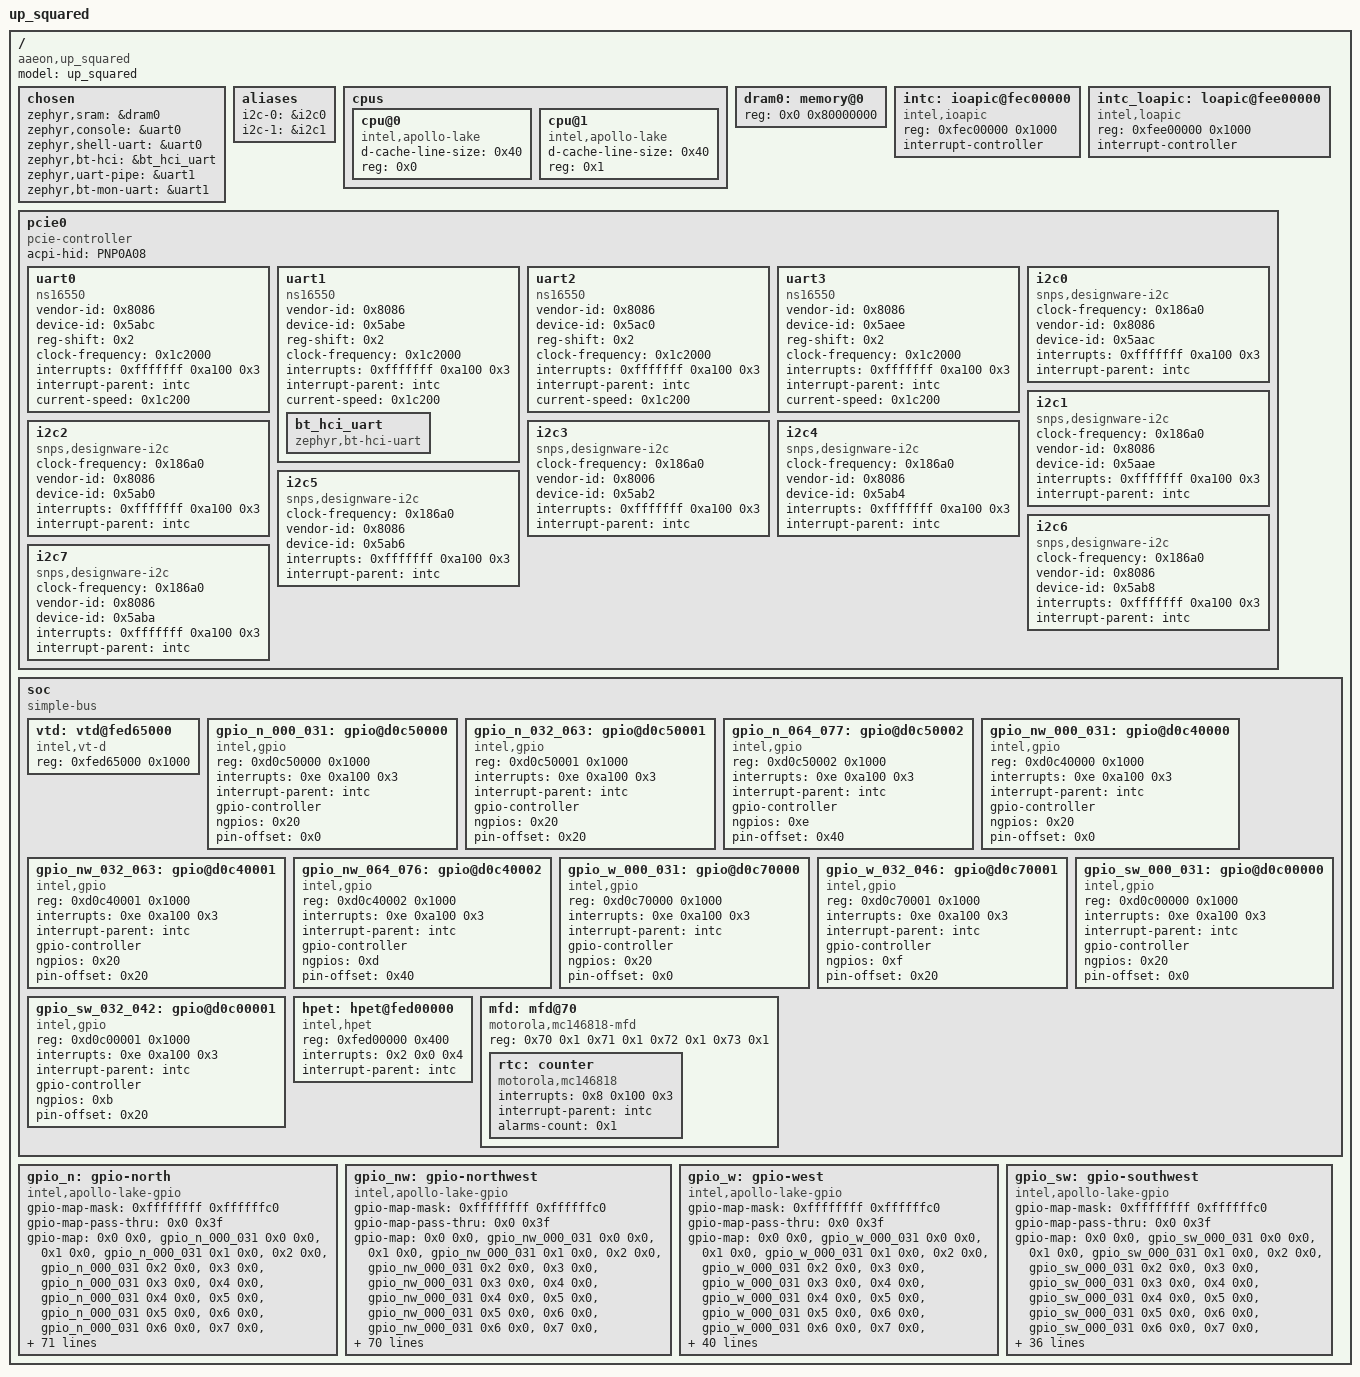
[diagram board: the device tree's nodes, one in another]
/dts-v1/;

/* node '/' defined in zephyr/dts/common/skeleton.dtsi:9 */
/ {
	#address-cells = < 0x1 >;        /* in zephyr/dts/common/skeleton.dtsi:10 */
	#size-cells = < 0x1 >;           /* in zephyr/dts/common/skeleton.dtsi:11 */
	model = "up_squared";            /* in zephyr/boards/up-bridge-the-gap/up_squared/up_squared.dts:16 */
	compatible = "aaeon,up_squared"; /* in zephyr/boards/up-bridge-the-gap/up_squared/up_squared.dts:17 */

	/* node '/chosen' defined in zephyr/dts/common/skeleton.dtsi:13 */
	chosen {
		zephyr,sram = &dram0;         /* in zephyr/boards/up-bridge-the-gap/up_squared/up_squared.dts:25 */
		zephyr,console = &uart0;      /* in zephyr/boards/up-bridge-the-gap/up_squared/up_squared.dts:26 */
		zephyr,shell-uart = &uart0;   /* in zephyr/boards/up-bridge-the-gap/up_squared/up_squared.dts:27 */
		zephyr,bt-hci = &bt_hci_uart; /* in zephyr/boards/up-bridge-the-gap/up_squared/up_squared.dts:28 */
		zephyr,uart-pipe = &uart1;    /* in zephyr/boards/up-bridge-the-gap/up_squared/up_squared.dts:29 */
		zephyr,bt-mon-uart = &uart1;  /* in zephyr/boards/up-bridge-the-gap/up_squared/up_squared.dts:30 */
	};

	/* node '/aliases' defined in zephyr/dts/common/skeleton.dtsi:15 */
	aliases {
		i2c-0 = &i2c0; /* in zephyr/boards/up-bridge-the-gap/up_squared/up_squared.dts:20 */
		i2c-1 = &i2c1; /* in zephyr/boards/up-bridge-the-gap/up_squared/up_squared.dts:21 */
	};

	/* node '/cpus' defined in zephyr/dts/x86/intel/apollo_lake.dtsi:13 */
	cpus {
		#address-cells = < 0x1 >; /* in zephyr/boards/up-bridge-the-gap/up_squared/up_squared.dts:34 */
		#size-cells = < 0x0 >;    /* in zephyr/boards/up-bridge-the-gap/up_squared/up_squared.dts:35 */

		/* node '/cpus/cpu@0' defined in zephyr/dts/x86/intel/apollo_lake.dtsi:17 */
		cpu@0 {
			device_type = "cpu";              /* in zephyr/boards/up-bridge-the-gap/up_squared/up_squared.dts:38 */
			compatible = "intel,apollo-lake",
			             "intel,x86_64";      /* in zephyr/boards/up-bridge-the-gap/up_squared/up_squared.dts:39 */
			d-cache-line-size = < 0x40 >;     /* in zephyr/boards/up-bridge-the-gap/up_squared/up_squared.dts:40 */
			reg = < 0x0 >;                    /* in zephyr/boards/up-bridge-the-gap/up_squared/up_squared.dts:41 */
		};

		/* node '/cpus/cpu@1' defined in zephyr/boards/up-bridge-the-gap/up_squared/up_squared.dts:44 */
		cpu@1 {
			device_type = "cpu";              /* in zephyr/boards/up-bridge-the-gap/up_squared/up_squared.dts:45 */
			compatible = "intel,apollo-lake",
			             "intel,x86_64";      /* in zephyr/boards/up-bridge-the-gap/up_squared/up_squared.dts:46 */
			d-cache-line-size = < 0x40 >;     /* in zephyr/boards/up-bridge-the-gap/up_squared/up_squared.dts:47 */
			reg = < 0x1 >;                    /* in zephyr/boards/up-bridge-the-gap/up_squared/up_squared.dts:48 */
		};
	};

	/* node '/memory@0' defined in zephyr/dts/x86/intel/apollo_lake.dtsi:25 */
	dram0: memory@0 {
		device_type = "memory";   /* in zephyr/dts/x86/intel/apollo_lake.dtsi:26 */
		reg = < 0x0 0x80000000 >; /* in zephyr/dts/x86/intel/apollo_lake.dtsi:27 */
	};

	/* node '/ioapic@fec00000' defined in zephyr/dts/x86/intel/apollo_lake.dtsi:30 */
	intc: ioapic@fec00000 {
		compatible = "intel,ioapic"; /* in zephyr/dts/x86/intel/apollo_lake.dtsi:31 */
		#address-cells = < 0x1 >;    /* in zephyr/dts/x86/intel/apollo_lake.dtsi:32 */
		#interrupt-cells = < 0x3 >;  /* in zephyr/dts/x86/intel/apollo_lake.dtsi:33 */
		reg = < 0xfec00000 0x1000 >; /* in zephyr/dts/x86/intel/apollo_lake.dtsi:34 */
		interrupt-controller;        /* in zephyr/dts/x86/intel/apollo_lake.dtsi:35 */
		phandle = < 0x1 >;           /* in zephyr/dts/x86/intel/apollo_lake.dtsi:62 */
	};

	/* node '/loapic@fee00000' defined in zephyr/dts/x86/intel/apollo_lake.dtsi:38 */
	intc_loapic: loapic@fee00000 {
		compatible = "intel,loapic"; /* in zephyr/dts/x86/intel/apollo_lake.dtsi:39 */
		reg = < 0xfee00000 0x1000 >; /* in zephyr/dts/x86/intel/apollo_lake.dtsi:40 */
		interrupt-controller;        /* in zephyr/dts/x86/intel/apollo_lake.dtsi:41 */
		#interrupt-cells = < 0x3 >;  /* in zephyr/dts/x86/intel/apollo_lake.dtsi:42 */
		#address-cells = < 0x1 >;    /* in zephyr/dts/x86/intel/apollo_lake.dtsi:43 */
	};

	/* node '/pcie0' defined in zephyr/dts/x86/intel/apollo_lake.dtsi:46 */
	pcie0: pcie0 {
		#address-cells = < 0x1 >;       /* in zephyr/dts/x86/intel/apollo_lake.dtsi:47 */
		#size-cells = < 0x1 >;          /* in zephyr/dts/x86/intel/apollo_lake.dtsi:48 */
		compatible = "pcie-controller"; /* in zephyr/dts/x86/intel/apollo_lake.dtsi:49 */
		acpi-hid = "PNP0A08";           /* in zephyr/dts/x86/intel/apollo_lake.dtsi:50 */
		ranges;                         /* in zephyr/dts/x86/intel/apollo_lake.dtsi:51 */

		/* node '/pcie0/uart0' defined in zephyr/dts/x86/intel/apollo_lake.dtsi:53 */
		uart0: uart0 {
			compatible = "ns16550";                /* in zephyr/dts/x86/intel/apollo_lake.dtsi:54 */
			vendor-id = < 0x8086 >;                /* in zephyr/dts/x86/intel/apollo_lake.dtsi:56 */
			device-id = < 0x5abc >;                /* in zephyr/dts/x86/intel/apollo_lake.dtsi:57 */
			reg-shift = < 0x2 >;                   /* in zephyr/dts/x86/intel/apollo_lake.dtsi:59 */
			clock-frequency = < 0x1c2000 >;        /* in zephyr/dts/x86/intel/apollo_lake.dtsi:60 */
			interrupts = < 0xfffffff 0xa100 0x3 >; /* in zephyr/dts/x86/intel/apollo_lake.dtsi:61 */
			interrupt-parent = < &intc >;          /* in zephyr/dts/x86/intel/apollo_lake.dtsi:62 */
			status = "okay";                       /* in zephyr/dts/x86/intel/apollo_lake.dtsi:63 */
			current-speed = < 0x1c200 >;           /* in zephyr/dts/x86/intel/apollo_lake.dtsi:64 */
		};

		/* node '/pcie0/uart1' defined in zephyr/dts/x86/intel/apollo_lake.dtsi:67 */
		uart1: uart1 {
			compatible = "ns16550";                /* in zephyr/dts/x86/intel/apollo_lake.dtsi:68 */
			vendor-id = < 0x8086 >;                /* in zephyr/dts/x86/intel/apollo_lake.dtsi:70 */
			device-id = < 0x5abe >;                /* in zephyr/dts/x86/intel/apollo_lake.dtsi:71 */
			reg-shift = < 0x2 >;                   /* in zephyr/dts/x86/intel/apollo_lake.dtsi:73 */
			clock-frequency = < 0x1c2000 >;        /* in zephyr/dts/x86/intel/apollo_lake.dtsi:74 */
			interrupts = < 0xfffffff 0xa100 0x3 >; /* in zephyr/dts/x86/intel/apollo_lake.dtsi:75 */
			interrupt-parent = < &intc >;          /* in zephyr/dts/x86/intel/apollo_lake.dtsi:76 */
			status = "okay";                       /* in zephyr/dts/x86/intel/apollo_lake.dtsi:78 */
			current-speed = < 0x1c200 >;           /* in zephyr/dts/x86/intel/apollo_lake.dtsi:79 */

			/* node '/pcie0/uart1/bt_hci_uart' defined in zephyr/boards/up-bridge-the-gap/up_squared/up_squared.dts:54 */
			bt_hci_uart: bt_hci_uart {
				compatible = "zephyr,bt-hci-uart"; /* in zephyr/boards/up-bridge-the-gap/up_squared/up_squared.dts:55 */
				status = "okay";                   /* in zephyr/boards/up-bridge-the-gap/up_squared/up_squared.dts:56 */
			};
		};

		/* node '/pcie0/uart2' defined in zephyr/dts/x86/intel/apollo_lake.dtsi:82 */
		uart2: uart2 {
			compatible = "ns16550";                /* in zephyr/dts/x86/intel/apollo_lake.dtsi:83 */
			vendor-id = < 0x8086 >;                /* in zephyr/dts/x86/intel/apollo_lake.dtsi:85 */
			device-id = < 0x5ac0 >;                /* in zephyr/dts/x86/intel/apollo_lake.dtsi:86 */
			reg-shift = < 0x2 >;                   /* in zephyr/dts/x86/intel/apollo_lake.dtsi:88 */
			clock-frequency = < 0x1c2000 >;        /* in zephyr/dts/x86/intel/apollo_lake.dtsi:89 */
			interrupts = < 0xfffffff 0xa100 0x3 >; /* in zephyr/dts/x86/intel/apollo_lake.dtsi:90 */
			interrupt-parent = < &intc >;          /* in zephyr/dts/x86/intel/apollo_lake.dtsi:91 */
			status = "okay";                       /* in zephyr/dts/x86/intel/apollo_lake.dtsi:93 */
			current-speed = < 0x1c200 >;           /* in zephyr/dts/x86/intel/apollo_lake.dtsi:94 */
		};

		/* node '/pcie0/uart3' defined in zephyr/dts/x86/intel/apollo_lake.dtsi:97 */
		uart3: uart3 {
			compatible = "ns16550";                /* in zephyr/dts/x86/intel/apollo_lake.dtsi:98 */
			vendor-id = < 0x8086 >;                /* in zephyr/dts/x86/intel/apollo_lake.dtsi:100 */
			device-id = < 0x5aee >;                /* in zephyr/dts/x86/intel/apollo_lake.dtsi:101 */
			reg-shift = < 0x2 >;                   /* in zephyr/dts/x86/intel/apollo_lake.dtsi:103 */
			clock-frequency = < 0x1c2000 >;        /* in zephyr/dts/x86/intel/apollo_lake.dtsi:104 */
			interrupts = < 0xfffffff 0xa100 0x3 >; /* in zephyr/dts/x86/intel/apollo_lake.dtsi:105 */
			interrupt-parent = < &intc >;          /* in zephyr/dts/x86/intel/apollo_lake.dtsi:106 */
			status = "okay";                       /* in zephyr/dts/x86/intel/apollo_lake.dtsi:108 */
			current-speed = < 0x1c200 >;           /* in zephyr/dts/x86/intel/apollo_lake.dtsi:109 */
		};

		/* node '/pcie0/i2c0' defined in zephyr/dts/x86/intel/apollo_lake.dtsi:112 */
		i2c0: i2c0 {
			compatible = "snps,designware-i2c";    /* in zephyr/dts/x86/intel/apollo_lake.dtsi:113 */
			clock-frequency = < 0x186a0 >;         /* in zephyr/dts/x86/intel/apollo_lake.dtsi:114 */
			#address-cells = < 0x1 >;              /* in zephyr/dts/x86/intel/apollo_lake.dtsi:115 */
			#size-cells = < 0x0 >;                 /* in zephyr/dts/x86/intel/apollo_lake.dtsi:116 */
			vendor-id = < 0x8086 >;                /* in zephyr/dts/x86/intel/apollo_lake.dtsi:117 */
			device-id = < 0x5aac >;                /* in zephyr/dts/x86/intel/apollo_lake.dtsi:118 */
			interrupts = < 0xfffffff 0xa100 0x3 >; /* in zephyr/dts/x86/intel/apollo_lake.dtsi:119 */
			interrupt-parent = < &intc >;          /* in zephyr/dts/x86/intel/apollo_lake.dtsi:120 */
			status = "okay";                       /* in zephyr/dts/x86/intel/apollo_lake.dtsi:122 */
		};

		/* node '/pcie0/i2c1' defined in zephyr/dts/x86/intel/apollo_lake.dtsi:125 */
		i2c1: i2c1 {
			compatible = "snps,designware-i2c";    /* in zephyr/dts/x86/intel/apollo_lake.dtsi:126 */
			clock-frequency = < 0x186a0 >;         /* in zephyr/dts/x86/intel/apollo_lake.dtsi:127 */
			#address-cells = < 0x1 >;              /* in zephyr/dts/x86/intel/apollo_lake.dtsi:128 */
			#size-cells = < 0x0 >;                 /* in zephyr/dts/x86/intel/apollo_lake.dtsi:129 */
			vendor-id = < 0x8086 >;                /* in zephyr/dts/x86/intel/apollo_lake.dtsi:130 */
			device-id = < 0x5aae >;                /* in zephyr/dts/x86/intel/apollo_lake.dtsi:131 */
			interrupts = < 0xfffffff 0xa100 0x3 >; /* in zephyr/dts/x86/intel/apollo_lake.dtsi:132 */
			interrupt-parent = < &intc >;          /* in zephyr/dts/x86/intel/apollo_lake.dtsi:133 */
			status = "okay";                       /* in zephyr/dts/x86/intel/apollo_lake.dtsi:135 */
		};

		/* node '/pcie0/i2c2' defined in zephyr/dts/x86/intel/apollo_lake.dtsi:138 */
		i2c2: i2c2 {
			compatible = "snps,designware-i2c";    /* in zephyr/dts/x86/intel/apollo_lake.dtsi:139 */
			clock-frequency = < 0x186a0 >;         /* in zephyr/dts/x86/intel/apollo_lake.dtsi:140 */
			#address-cells = < 0x1 >;              /* in zephyr/dts/x86/intel/apollo_lake.dtsi:141 */
			#size-cells = < 0x0 >;                 /* in zephyr/dts/x86/intel/apollo_lake.dtsi:142 */
			vendor-id = < 0x8086 >;                /* in zephyr/dts/x86/intel/apollo_lake.dtsi:143 */
			device-id = < 0x5ab0 >;                /* in zephyr/dts/x86/intel/apollo_lake.dtsi:144 */
			interrupts = < 0xfffffff 0xa100 0x3 >; /* in zephyr/dts/x86/intel/apollo_lake.dtsi:145 */
			interrupt-parent = < &intc >;          /* in zephyr/dts/x86/intel/apollo_lake.dtsi:146 */
			status = "okay";                       /* in zephyr/dts/x86/intel/apollo_lake.dtsi:148 */
		};

		/* node '/pcie0/i2c3' defined in zephyr/dts/x86/intel/apollo_lake.dtsi:151 */
		i2c3: i2c3 {
			compatible = "snps,designware-i2c";    /* in zephyr/dts/x86/intel/apollo_lake.dtsi:152 */
			clock-frequency = < 0x186a0 >;         /* in zephyr/dts/x86/intel/apollo_lake.dtsi:153 */
			#address-cells = < 0x1 >;              /* in zephyr/dts/x86/intel/apollo_lake.dtsi:154 */
			#size-cells = < 0x0 >;                 /* in zephyr/dts/x86/intel/apollo_lake.dtsi:155 */
			vendor-id = < 0x8006 >;                /* in zephyr/dts/x86/intel/apollo_lake.dtsi:156 */
			device-id = < 0x5ab2 >;                /* in zephyr/dts/x86/intel/apollo_lake.dtsi:157 */
			interrupts = < 0xfffffff 0xa100 0x3 >; /* in zephyr/dts/x86/intel/apollo_lake.dtsi:158 */
			interrupt-parent = < &intc >;          /* in zephyr/dts/x86/intel/apollo_lake.dtsi:159 */
			status = "okay";                       /* in zephyr/dts/x86/intel/apollo_lake.dtsi:161 */
		};

		/* node '/pcie0/i2c4' defined in zephyr/dts/x86/intel/apollo_lake.dtsi:164 */
		i2c4: i2c4 {
			compatible = "snps,designware-i2c";    /* in zephyr/dts/x86/intel/apollo_lake.dtsi:165 */
			clock-frequency = < 0x186a0 >;         /* in zephyr/dts/x86/intel/apollo_lake.dtsi:166 */
			#address-cells = < 0x1 >;              /* in zephyr/dts/x86/intel/apollo_lake.dtsi:167 */
			#size-cells = < 0x0 >;                 /* in zephyr/dts/x86/intel/apollo_lake.dtsi:168 */
			vendor-id = < 0x8086 >;                /* in zephyr/dts/x86/intel/apollo_lake.dtsi:169 */
			device-id = < 0x5ab4 >;                /* in zephyr/dts/x86/intel/apollo_lake.dtsi:170 */
			interrupts = < 0xfffffff 0xa100 0x3 >; /* in zephyr/dts/x86/intel/apollo_lake.dtsi:171 */
			interrupt-parent = < &intc >;          /* in zephyr/dts/x86/intel/apollo_lake.dtsi:172 */
			status = "okay";                       /* in zephyr/dts/x86/intel/apollo_lake.dtsi:174 */
		};

		/* node '/pcie0/i2c5' defined in zephyr/dts/x86/intel/apollo_lake.dtsi:177 */
		i2c5: i2c5 {
			compatible = "snps,designware-i2c";    /* in zephyr/dts/x86/intel/apollo_lake.dtsi:178 */
			clock-frequency = < 0x186a0 >;         /* in zephyr/dts/x86/intel/apollo_lake.dtsi:179 */
			#address-cells = < 0x1 >;              /* in zephyr/dts/x86/intel/apollo_lake.dtsi:180 */
			#size-cells = < 0x0 >;                 /* in zephyr/dts/x86/intel/apollo_lake.dtsi:181 */
			vendor-id = < 0x8086 >;                /* in zephyr/dts/x86/intel/apollo_lake.dtsi:182 */
			device-id = < 0x5ab6 >;                /* in zephyr/dts/x86/intel/apollo_lake.dtsi:183 */
			interrupts = < 0xfffffff 0xa100 0x3 >; /* in zephyr/dts/x86/intel/apollo_lake.dtsi:184 */
			interrupt-parent = < &intc >;          /* in zephyr/dts/x86/intel/apollo_lake.dtsi:185 */
			status = "okay";                       /* in zephyr/dts/x86/intel/apollo_lake.dtsi:187 */
		};

		/* node '/pcie0/i2c6' defined in zephyr/dts/x86/intel/apollo_lake.dtsi:190 */
		i2c6: i2c6 {
			compatible = "snps,designware-i2c";    /* in zephyr/dts/x86/intel/apollo_lake.dtsi:191 */
			clock-frequency = < 0x186a0 >;         /* in zephyr/dts/x86/intel/apollo_lake.dtsi:192 */
			#address-cells = < 0x1 >;              /* in zephyr/dts/x86/intel/apollo_lake.dtsi:193 */
			#size-cells = < 0x0 >;                 /* in zephyr/dts/x86/intel/apollo_lake.dtsi:194 */
			vendor-id = < 0x8086 >;                /* in zephyr/dts/x86/intel/apollo_lake.dtsi:195 */
			device-id = < 0x5ab8 >;                /* in zephyr/dts/x86/intel/apollo_lake.dtsi:196 */
			interrupts = < 0xfffffff 0xa100 0x3 >; /* in zephyr/dts/x86/intel/apollo_lake.dtsi:197 */
			interrupt-parent = < &intc >;          /* in zephyr/dts/x86/intel/apollo_lake.dtsi:198 */
			status = "okay";                       /* in zephyr/dts/x86/intel/apollo_lake.dtsi:200 */
		};

		/* node '/pcie0/i2c7' defined in zephyr/dts/x86/intel/apollo_lake.dtsi:203 */
		i2c7: i2c7 {
			compatible = "snps,designware-i2c";    /* in zephyr/dts/x86/intel/apollo_lake.dtsi:204 */
			clock-frequency = < 0x186a0 >;         /* in zephyr/dts/x86/intel/apollo_lake.dtsi:205 */
			#address-cells = < 0x1 >;              /* in zephyr/dts/x86/intel/apollo_lake.dtsi:206 */
			#size-cells = < 0x0 >;                 /* in zephyr/dts/x86/intel/apollo_lake.dtsi:207 */
			vendor-id = < 0x8086 >;                /* in zephyr/dts/x86/intel/apollo_lake.dtsi:208 */
			device-id = < 0x5aba >;                /* in zephyr/dts/x86/intel/apollo_lake.dtsi:209 */
			interrupts = < 0xfffffff 0xa100 0x3 >; /* in zephyr/dts/x86/intel/apollo_lake.dtsi:210 */
			interrupt-parent = < &intc >;          /* in zephyr/dts/x86/intel/apollo_lake.dtsi:211 */
			status = "okay";                       /* in zephyr/dts/x86/intel/apollo_lake.dtsi:213 */
		};
	};

	/* node '/soc' defined in zephyr/dts/x86/intel/apollo_lake.dtsi:217 */
	soc {
		#address-cells = < 0x1 >;  /* in zephyr/dts/x86/intel/apollo_lake.dtsi:218 */
		#size-cells = < 0x1 >;     /* in zephyr/dts/x86/intel/apollo_lake.dtsi:219 */
		compatible = "simple-bus"; /* in zephyr/dts/x86/intel/apollo_lake.dtsi:220 */
		ranges;                    /* in zephyr/dts/x86/intel/apollo_lake.dtsi:221 */

		/* node '/soc/vtd@fed65000' defined in zephyr/dts/x86/intel/apollo_lake.dtsi:223 */
		vtd: vtd@fed65000 {
			compatible = "intel,vt-d";   /* in zephyr/dts/x86/intel/apollo_lake.dtsi:224 */
			reg = < 0xfed65000 0x1000 >; /* in zephyr/dts/x86/intel/apollo_lake.dtsi:226 */
			status = "okay";             /* in zephyr/dts/x86/intel/apollo_lake.dtsi:228 */
		};

		/* node '/soc/gpio@d0c50000' defined in zephyr/dts/x86/intel/apollo_lake.dtsi:231 */
		gpio_n_000_031: gpio@d0c50000 {
			compatible = "intel,gpio";       /* in zephyr/dts/x86/intel/apollo_lake.dtsi:232 */
			reg = < 0xd0c50000 0x1000 >;     /* in zephyr/dts/x86/intel/apollo_lake.dtsi:233 */
			interrupts = < 0xe 0xa100 0x3 >; /* in zephyr/dts/x86/intel/apollo_lake.dtsi:234 */
			interrupt-parent = < &intc >;    /* in zephyr/dts/x86/intel/apollo_lake.dtsi:235 */
			gpio-controller;                 /* in zephyr/dts/x86/intel/apollo_lake.dtsi:237 */
			#gpio-cells = < 0x2 >;           /* in zephyr/dts/x86/intel/apollo_lake.dtsi:238 */
			ngpios = < 0x20 >;               /* in zephyr/dts/x86/intel/apollo_lake.dtsi:240 */
			pin-offset = < 0x0 >;            /* in zephyr/dts/x86/intel/apollo_lake.dtsi:241 */
			status = "okay";                 /* in zephyr/dts/x86/intel/apollo_lake.dtsi:243 */
			phandle = < 0x2 >;               /* in zephyr/dts/x86/intel/apollo_lake.dtsi:414 */
		};

		/* node '/soc/gpio@d0c50001' defined in zephyr/dts/x86/intel/apollo_lake.dtsi:246 */
		gpio_n_032_063: gpio@d0c50001 {
			compatible = "intel,gpio";       /* in zephyr/dts/x86/intel/apollo_lake.dtsi:247 */
			reg = < 0xd0c50001 0x1000 >;     /* in zephyr/dts/x86/intel/apollo_lake.dtsi:248 */
			interrupts = < 0xe 0xa100 0x3 >; /* in zephyr/dts/x86/intel/apollo_lake.dtsi:249 */
			interrupt-parent = < &intc >;    /* in zephyr/dts/x86/intel/apollo_lake.dtsi:250 */
			gpio-controller;                 /* in zephyr/dts/x86/intel/apollo_lake.dtsi:252 */
			#gpio-cells = < 0x2 >;           /* in zephyr/dts/x86/intel/apollo_lake.dtsi:253 */
			ngpios = < 0x20 >;               /* in zephyr/dts/x86/intel/apollo_lake.dtsi:255 */
			pin-offset = < 0x20 >;           /* in zephyr/dts/x86/intel/apollo_lake.dtsi:256 */
			status = "okay";                 /* in zephyr/dts/x86/intel/apollo_lake.dtsi:258 */
			phandle = < 0x3 >;               /* in zephyr/dts/x86/intel/apollo_lake.dtsi:414 */
		};

		/* node '/soc/gpio@d0c50002' defined in zephyr/dts/x86/intel/apollo_lake.dtsi:261 */
		gpio_n_064_077: gpio@d0c50002 {
			compatible = "intel,gpio";       /* in zephyr/dts/x86/intel/apollo_lake.dtsi:262 */
			reg = < 0xd0c50002 0x1000 >;     /* in zephyr/dts/x86/intel/apollo_lake.dtsi:263 */
			interrupts = < 0xe 0xa100 0x3 >; /* in zephyr/dts/x86/intel/apollo_lake.dtsi:264 */
			interrupt-parent = < &intc >;    /* in zephyr/dts/x86/intel/apollo_lake.dtsi:265 */
			gpio-controller;                 /* in zephyr/dts/x86/intel/apollo_lake.dtsi:267 */
			#gpio-cells = < 0x2 >;           /* in zephyr/dts/x86/intel/apollo_lake.dtsi:268 */
			ngpios = < 0xe >;                /* in zephyr/dts/x86/intel/apollo_lake.dtsi:270 */
			pin-offset = < 0x40 >;           /* in zephyr/dts/x86/intel/apollo_lake.dtsi:271 */
			status = "okay";                 /* in zephyr/dts/x86/intel/apollo_lake.dtsi:273 */
			phandle = < 0x4 >;               /* in zephyr/dts/x86/intel/apollo_lake.dtsi:414 */
		};

		/* node '/soc/gpio@d0c40000' defined in zephyr/dts/x86/intel/apollo_lake.dtsi:276 */
		gpio_nw_000_031: gpio@d0c40000 {
			compatible = "intel,gpio";       /* in zephyr/dts/x86/intel/apollo_lake.dtsi:277 */
			reg = < 0xd0c40000 0x1000 >;     /* in zephyr/dts/x86/intel/apollo_lake.dtsi:278 */
			interrupts = < 0xe 0xa100 0x3 >; /* in zephyr/dts/x86/intel/apollo_lake.dtsi:279 */
			interrupt-parent = < &intc >;    /* in zephyr/dts/x86/intel/apollo_lake.dtsi:280 */
			gpio-controller;                 /* in zephyr/dts/x86/intel/apollo_lake.dtsi:282 */
			#gpio-cells = < 0x2 >;           /* in zephyr/dts/x86/intel/apollo_lake.dtsi:283 */
			ngpios = < 0x20 >;               /* in zephyr/dts/x86/intel/apollo_lake.dtsi:285 */
			pin-offset = < 0x0 >;            /* in zephyr/dts/x86/intel/apollo_lake.dtsi:286 */
			status = "okay";                 /* in zephyr/dts/x86/intel/apollo_lake.dtsi:288 */
			phandle = < 0x5 >;               /* in zephyr/dts/x86/intel/apollo_lake.dtsi:500 */
		};

		/* node '/soc/gpio@d0c40001' defined in zephyr/dts/x86/intel/apollo_lake.dtsi:291 */
		gpio_nw_032_063: gpio@d0c40001 {
			compatible = "intel,gpio";       /* in zephyr/dts/x86/intel/apollo_lake.dtsi:292 */
			reg = < 0xd0c40001 0x1000 >;     /* in zephyr/dts/x86/intel/apollo_lake.dtsi:293 */
			interrupts = < 0xe 0xa100 0x3 >; /* in zephyr/dts/x86/intel/apollo_lake.dtsi:294 */
			interrupt-parent = < &intc >;    /* in zephyr/dts/x86/intel/apollo_lake.dtsi:295 */
			gpio-controller;                 /* in zephyr/dts/x86/intel/apollo_lake.dtsi:297 */
			#gpio-cells = < 0x2 >;           /* in zephyr/dts/x86/intel/apollo_lake.dtsi:298 */
			ngpios = < 0x20 >;               /* in zephyr/dts/x86/intel/apollo_lake.dtsi:300 */
			pin-offset = < 0x20 >;           /* in zephyr/dts/x86/intel/apollo_lake.dtsi:301 */
			status = "okay";                 /* in zephyr/dts/x86/intel/apollo_lake.dtsi:303 */
			phandle = < 0x6 >;               /* in zephyr/dts/x86/intel/apollo_lake.dtsi:500 */
		};

		/* node '/soc/gpio@d0c40002' defined in zephyr/dts/x86/intel/apollo_lake.dtsi:306 */
		gpio_nw_064_076: gpio@d0c40002 {
			compatible = "intel,gpio";       /* in zephyr/dts/x86/intel/apollo_lake.dtsi:307 */
			reg = < 0xd0c40002 0x1000 >;     /* in zephyr/dts/x86/intel/apollo_lake.dtsi:308 */
			interrupts = < 0xe 0xa100 0x3 >; /* in zephyr/dts/x86/intel/apollo_lake.dtsi:309 */
			interrupt-parent = < &intc >;    /* in zephyr/dts/x86/intel/apollo_lake.dtsi:310 */
			gpio-controller;                 /* in zephyr/dts/x86/intel/apollo_lake.dtsi:312 */
			#gpio-cells = < 0x2 >;           /* in zephyr/dts/x86/intel/apollo_lake.dtsi:313 */
			ngpios = < 0xd >;                /* in zephyr/dts/x86/intel/apollo_lake.dtsi:315 */
			pin-offset = < 0x40 >;           /* in zephyr/dts/x86/intel/apollo_lake.dtsi:316 */
			status = "okay";                 /* in zephyr/dts/x86/intel/apollo_lake.dtsi:318 */
			phandle = < 0x7 >;               /* in zephyr/dts/x86/intel/apollo_lake.dtsi:500 */
		};

		/* node '/soc/gpio@d0c70000' defined in zephyr/dts/x86/intel/apollo_lake.dtsi:321 */
		gpio_w_000_031: gpio@d0c70000 {
			compatible = "intel,gpio";       /* in zephyr/dts/x86/intel/apollo_lake.dtsi:322 */
			reg = < 0xd0c70000 0x1000 >;     /* in zephyr/dts/x86/intel/apollo_lake.dtsi:323 */
			interrupts = < 0xe 0xa100 0x3 >; /* in zephyr/dts/x86/intel/apollo_lake.dtsi:324 */
			interrupt-parent = < &intc >;    /* in zephyr/dts/x86/intel/apollo_lake.dtsi:325 */
			gpio-controller;                 /* in zephyr/dts/x86/intel/apollo_lake.dtsi:327 */
			#gpio-cells = < 0x2 >;           /* in zephyr/dts/x86/intel/apollo_lake.dtsi:328 */
			ngpios = < 0x20 >;               /* in zephyr/dts/x86/intel/apollo_lake.dtsi:330 */
			pin-offset = < 0x0 >;            /* in zephyr/dts/x86/intel/apollo_lake.dtsi:331 */
			status = "okay";                 /* in zephyr/dts/x86/intel/apollo_lake.dtsi:333 */
			phandle = < 0x8 >;               /* in zephyr/dts/x86/intel/apollo_lake.dtsi:585 */
		};

		/* node '/soc/gpio@d0c70001' defined in zephyr/dts/x86/intel/apollo_lake.dtsi:336 */
		gpio_w_032_046: gpio@d0c70001 {
			compatible = "intel,gpio";       /* in zephyr/dts/x86/intel/apollo_lake.dtsi:337 */
			reg = < 0xd0c70001 0x1000 >;     /* in zephyr/dts/x86/intel/apollo_lake.dtsi:338 */
			interrupts = < 0xe 0xa100 0x3 >; /* in zephyr/dts/x86/intel/apollo_lake.dtsi:339 */
			interrupt-parent = < &intc >;    /* in zephyr/dts/x86/intel/apollo_lake.dtsi:340 */
			gpio-controller;                 /* in zephyr/dts/x86/intel/apollo_lake.dtsi:342 */
			#gpio-cells = < 0x2 >;           /* in zephyr/dts/x86/intel/apollo_lake.dtsi:343 */
			ngpios = < 0xf >;                /* in zephyr/dts/x86/intel/apollo_lake.dtsi:345 */
			pin-offset = < 0x20 >;           /* in zephyr/dts/x86/intel/apollo_lake.dtsi:346 */
			status = "okay";                 /* in zephyr/dts/x86/intel/apollo_lake.dtsi:348 */
			phandle = < 0x9 >;               /* in zephyr/dts/x86/intel/apollo_lake.dtsi:585 */
		};

		/* node '/soc/gpio@d0c00000' defined in zephyr/dts/x86/intel/apollo_lake.dtsi:351 */
		gpio_sw_000_031: gpio@d0c00000 {
			compatible = "intel,gpio";       /* in zephyr/dts/x86/intel/apollo_lake.dtsi:352 */
			reg = < 0xd0c00000 0x1000 >;     /* in zephyr/dts/x86/intel/apollo_lake.dtsi:353 */
			interrupts = < 0xe 0xa100 0x3 >; /* in zephyr/dts/x86/intel/apollo_lake.dtsi:354 */
			interrupt-parent = < &intc >;    /* in zephyr/dts/x86/intel/apollo_lake.dtsi:355 */
			gpio-controller;                 /* in zephyr/dts/x86/intel/apollo_lake.dtsi:357 */
			#gpio-cells = < 0x2 >;           /* in zephyr/dts/x86/intel/apollo_lake.dtsi:358 */
			ngpios = < 0x20 >;               /* in zephyr/dts/x86/intel/apollo_lake.dtsi:360 */
			pin-offset = < 0x0 >;            /* in zephyr/dts/x86/intel/apollo_lake.dtsi:361 */
			status = "okay";                 /* in zephyr/dts/x86/intel/apollo_lake.dtsi:363 */
			phandle = < 0xa >;               /* in zephyr/dts/x86/intel/apollo_lake.dtsi:640 */
		};

		/* node '/soc/gpio@d0c00001' defined in zephyr/dts/x86/intel/apollo_lake.dtsi:366 */
		gpio_sw_032_042: gpio@d0c00001 {
			compatible = "intel,gpio";       /* in zephyr/dts/x86/intel/apollo_lake.dtsi:367 */
			reg = < 0xd0c00001 0x1000 >;     /* in zephyr/dts/x86/intel/apollo_lake.dtsi:368 */
			interrupts = < 0xe 0xa100 0x3 >; /* in zephyr/dts/x86/intel/apollo_lake.dtsi:369 */
			interrupt-parent = < &intc >;    /* in zephyr/dts/x86/intel/apollo_lake.dtsi:370 */
			gpio-controller;                 /* in zephyr/dts/x86/intel/apollo_lake.dtsi:372 */
			#gpio-cells = < 0x2 >;           /* in zephyr/dts/x86/intel/apollo_lake.dtsi:373 */
			ngpios = < 0xb >;                /* in zephyr/dts/x86/intel/apollo_lake.dtsi:375 */
			pin-offset = < 0x20 >;           /* in zephyr/dts/x86/intel/apollo_lake.dtsi:376 */
			status = "okay";                 /* in zephyr/dts/x86/intel/apollo_lake.dtsi:378 */
			phandle = < 0xb >;               /* in zephyr/dts/x86/intel/apollo_lake.dtsi:640 */
		};

		/* node '/soc/hpet@fed00000' defined in zephyr/dts/x86/intel/apollo_lake.dtsi:381 */
		hpet: hpet@fed00000 {
			compatible = "intel,hpet";    /* in zephyr/dts/x86/intel/apollo_lake.dtsi:382 */
			reg = < 0xfed00000 0x400 >;   /* in zephyr/dts/x86/intel/apollo_lake.dtsi:383 */
			interrupts = < 0x2 0x0 0x4 >; /* in zephyr/dts/x86/intel/apollo_lake.dtsi:384 */
			interrupt-parent = < &intc >; /* in zephyr/dts/x86/intel/apollo_lake.dtsi:385 */
			status = "okay";              /* in zephyr/dts/x86/intel/apollo_lake.dtsi:387 */
		};

		/* node '/soc/mfd@70' defined in zephyr/dts/x86/intel/apollo_lake.dtsi:390 */
		mfd: mfd@70 {
			compatible = "motorola,mc146818-mfd";          /* in zephyr/dts/x86/intel/apollo_lake.dtsi:391 */
			reg = < 0x70 0x1 0x71 0x1 0x72 0x1 0x73 0x1 >; /* in zephyr/dts/x86/intel/apollo_lake.dtsi:392 */
			status = "okay";                               /* in zephyr/dts/x86/intel/apollo_lake.dtsi:403 */

			/* node '/soc/mfd@70/rtc' defined in zephyr/dts/x86/intel/apollo_lake.dtsi:394 */
			rtc: counter: rtc {
				compatible = "motorola,mc146818"; /* in zephyr/dts/x86/intel/apollo_lake.dtsi:395 */
				interrupts = < 0x8 0x100 0x3 >;   /* in zephyr/dts/x86/intel/apollo_lake.dtsi:396 */
				interrupt-parent = < &intc >;     /* in zephyr/dts/x86/intel/apollo_lake.dtsi:397 */
				alarms-count = < 0x1 >;           /* in zephyr/dts/x86/intel/apollo_lake.dtsi:398 */
				status = "okay";                  /* in zephyr/dts/x86/intel/apollo_lake.dtsi:400 */
			};
		};
	};

	/* node '/gpio-north' defined in zephyr/dts/x86/intel/apollo_lake.dtsi:408 */
	gpio_n: gpio-north {
		compatible = "intel,apollo-lake-gpio";            /* in zephyr/dts/x86/intel/apollo_lake.dtsi:410 */
		#gpio-cells = < 0x2 >;                            /* in zephyr/dts/x86/intel/apollo_lake.dtsi:411 */
		gpio-map-mask = < 0xffffffff 0xffffffc0 >;        /* in zephyr/dts/x86/intel/apollo_lake.dtsi:412 */
		gpio-map-pass-thru = < 0x0 0x3f >;                /* in zephyr/dts/x86/intel/apollo_lake.dtsi:413 */
		gpio-map = < 0x0 0x0 &gpio_n_000_031 0x0 0x0 >,
		           < 0x1 0x0 &gpio_n_000_031 0x1 0x0 >,
		           < 0x2 0x0 &gpio_n_000_031 0x2 0x0 >,
		           < 0x3 0x0 &gpio_n_000_031 0x3 0x0 >,
		           < 0x4 0x0 &gpio_n_000_031 0x4 0x0 >,
		           < 0x5 0x0 &gpio_n_000_031 0x5 0x0 >,
		           < 0x6 0x0 &gpio_n_000_031 0x6 0x0 >,
		           < 0x7 0x0 &gpio_n_000_031 0x7 0x0 >,
		           < 0x8 0x0 &gpio_n_000_031 0x8 0x0 >,
		           < 0x9 0x0 &gpio_n_000_031 0x9 0x0 >,
		           < 0xa 0x0 &gpio_n_000_031 0xa 0x0 >,
		           < 0xb 0x0 &gpio_n_000_031 0xb 0x0 >,
		           < 0xc 0x0 &gpio_n_000_031 0xc 0x0 >,
		           < 0xd 0x0 &gpio_n_000_031 0xd 0x0 >,
		           < 0xe 0x0 &gpio_n_000_031 0xe 0x0 >,
		           < 0xf 0x0 &gpio_n_000_031 0xf 0x0 >,
		           < 0x10 0x0 &gpio_n_000_031 0x10 0x0 >,
		           < 0x11 0x0 &gpio_n_000_031 0x11 0x0 >,
		           < 0x12 0x0 &gpio_n_000_031 0x12 0x0 >,
		           < 0x13 0x0 &gpio_n_000_031 0x13 0x0 >,
		           < 0x14 0x0 &gpio_n_000_031 0x14 0x0 >,
		           < 0x15 0x0 &gpio_n_000_031 0x15 0x0 >,
		           < 0x16 0x0 &gpio_n_000_031 0x16 0x0 >,
		           < 0x17 0x0 &gpio_n_000_031 0x17 0x0 >,
		           < 0x18 0x0 &gpio_n_000_031 0x18 0x0 >,
		           < 0x19 0x0 &gpio_n_000_031 0x19 0x0 >,
		           < 0x1a 0x0 &gpio_n_000_031 0x1a 0x0 >,
		           < 0x1b 0x0 &gpio_n_000_031 0x1b 0x0 >,
		           < 0x1c 0x0 &gpio_n_000_031 0x1c 0x0 >,
		           < 0x1d 0x0 &gpio_n_000_031 0x1d 0x0 >,
		           < 0x1e 0x0 &gpio_n_000_031 0x1e 0x0 >,
		           < 0x1f 0x0 &gpio_n_000_031 0x1f 0x0 >,
		           < 0x20 0x0 &gpio_n_032_063 0x0 0x0 >,
		           < 0x21 0x0 &gpio_n_032_063 0x1 0x0 >,
		           < 0x22 0x0 &gpio_n_032_063 0x2 0x0 >,
		           < 0x23 0x0 &gpio_n_032_063 0x3 0x0 >,
		           < 0x24 0x0 &gpio_n_032_063 0x4 0x0 >,
		           < 0x25 0x0 &gpio_n_032_063 0x5 0x0 >,
		           < 0x26 0x0 &gpio_n_032_063 0x6 0x0 >,
		           < 0x27 0x0 &gpio_n_032_063 0x7 0x0 >,
		           < 0x28 0x0 &gpio_n_032_063 0x8 0x0 >,
		           < 0x29 0x0 &gpio_n_032_063 0x9 0x0 >,
		           < 0x2a 0x0 &gpio_n_032_063 0xa 0x0 >,
		           < 0x2b 0x0 &gpio_n_032_063 0xb 0x0 >,
		           < 0x2c 0x0 &gpio_n_032_063 0xc 0x0 >,
		           < 0x2d 0x0 &gpio_n_032_063 0xd 0x0 >,
		           < 0x2e 0x0 &gpio_n_032_063 0xe 0x0 >,
		           < 0x2f 0x0 &gpio_n_032_063 0xf 0x0 >,
		           < 0x30 0x0 &gpio_n_032_063 0x10 0x0 >,
		           < 0x31 0x0 &gpio_n_032_063 0x11 0x0 >,
		           < 0x32 0x0 &gpio_n_032_063 0x12 0x0 >,
		           < 0x33 0x0 &gpio_n_032_063 0x13 0x0 >,
		           < 0x34 0x0 &gpio_n_032_063 0x14 0x0 >,
		           < 0x35 0x0 &gpio_n_032_063 0x15 0x0 >,
		           < 0x36 0x0 &gpio_n_032_063 0x16 0x0 >,
		           < 0x37 0x0 &gpio_n_032_063 0x17 0x0 >,
		           < 0x38 0x0 &gpio_n_032_063 0x18 0x0 >,
		           < 0x39 0x0 &gpio_n_032_063 0x19 0x0 >,
		           < 0x3a 0x0 &gpio_n_032_063 0x1a 0x0 >,
		           < 0x3b 0x0 &gpio_n_032_063 0x1b 0x0 >,
		           < 0x3c 0x0 &gpio_n_032_063 0x1c 0x0 >,
		           < 0x3d 0x0 &gpio_n_032_063 0x1d 0x0 >,
		           < 0x3e 0x0 &gpio_n_032_063 0x1e 0x0 >,
		           < 0x3f 0x0 &gpio_n_032_063 0x1f 0x0 >,
		           < 0x40 0x0 &gpio_n_064_077 0x0 0x0 >,
		           < 0x41 0x0 &gpio_n_064_077 0x1 0x0 >,
		           < 0x42 0x0 &gpio_n_064_077 0x2 0x0 >,
		           < 0x43 0x0 &gpio_n_064_077 0x3 0x0 >,
		           < 0x44 0x0 &gpio_n_064_077 0x4 0x0 >,
		           < 0x45 0x0 &gpio_n_064_077 0x5 0x0 >,
		           < 0x46 0x0 &gpio_n_064_077 0x6 0x0 >,
		           < 0x47 0x0 &gpio_n_064_077 0x7 0x0 >,
		           < 0x48 0x0 &gpio_n_064_077 0x8 0x0 >,
		           < 0x49 0x0 &gpio_n_064_077 0x9 0x0 >,
		           < 0x4a 0x0 &gpio_n_064_077 0xa 0x0 >,
		           < 0x4b 0x0 &gpio_n_064_077 0xb 0x0 >,
		           < 0x4c 0x0 &gpio_n_064_077 0xc 0x0 >,
		           < 0x4d 0x0 &gpio_n_064_077 0xd 0x0 >;  /* in zephyr/dts/x86/intel/apollo_lake.dtsi:414 */
	};

	/* node '/gpio-northwest' defined in zephyr/dts/x86/intel/apollo_lake.dtsi:494 */
	gpio_nw: gpio-northwest {
		compatible = "intel,apollo-lake-gpio";             /* in zephyr/dts/x86/intel/apollo_lake.dtsi:496 */
		#gpio-cells = < 0x2 >;                             /* in zephyr/dts/x86/intel/apollo_lake.dtsi:497 */
		gpio-map-mask = < 0xffffffff 0xffffffc0 >;         /* in zephyr/dts/x86/intel/apollo_lake.dtsi:498 */
		gpio-map-pass-thru = < 0x0 0x3f >;                 /* in zephyr/dts/x86/intel/apollo_lake.dtsi:499 */
		gpio-map = < 0x0 0x0 &gpio_nw_000_031 0x0 0x0 >,
		           < 0x1 0x0 &gpio_nw_000_031 0x1 0x0 >,
		           < 0x2 0x0 &gpio_nw_000_031 0x2 0x0 >,
		           < 0x3 0x0 &gpio_nw_000_031 0x3 0x0 >,
		           < 0x4 0x0 &gpio_nw_000_031 0x4 0x0 >,
		           < 0x5 0x0 &gpio_nw_000_031 0x5 0x0 >,
		           < 0x6 0x0 &gpio_nw_000_031 0x6 0x0 >,
		           < 0x7 0x0 &gpio_nw_000_031 0x7 0x0 >,
		           < 0x8 0x0 &gpio_nw_000_031 0x8 0x0 >,
		           < 0x9 0x0 &gpio_nw_000_031 0x9 0x0 >,
		           < 0xa 0x0 &gpio_nw_000_031 0xa 0x0 >,
		           < 0xb 0x0 &gpio_nw_000_031 0xb 0x0 >,
		           < 0xc 0x0 &gpio_nw_000_031 0xc 0x0 >,
		           < 0xd 0x0 &gpio_nw_000_031 0xd 0x0 >,
		           < 0xe 0x0 &gpio_nw_000_031 0xe 0x0 >,
		           < 0xf 0x0 &gpio_nw_000_031 0xf 0x0 >,
		           < 0x10 0x0 &gpio_nw_000_031 0x10 0x0 >,
		           < 0x11 0x0 &gpio_nw_000_031 0x11 0x0 >,
		           < 0x12 0x0 &gpio_nw_000_031 0x12 0x0 >,
		           < 0x13 0x0 &gpio_nw_000_031 0x13 0x0 >,
		           < 0x14 0x0 &gpio_nw_000_031 0x14 0x0 >,
		           < 0x15 0x0 &gpio_nw_000_031 0x15 0x0 >,
		           < 0x16 0x0 &gpio_nw_000_031 0x16 0x0 >,
		           < 0x17 0x0 &gpio_nw_000_031 0x17 0x0 >,
		           < 0x18 0x0 &gpio_nw_000_031 0x18 0x0 >,
		           < 0x19 0x0 &gpio_nw_000_031 0x19 0x0 >,
		           < 0x1a 0x0 &gpio_nw_000_031 0x1a 0x0 >,
		           < 0x1b 0x0 &gpio_nw_000_031 0x1b 0x0 >,
		           < 0x1c 0x0 &gpio_nw_000_031 0x1c 0x0 >,
		           < 0x1d 0x0 &gpio_nw_000_031 0x1d 0x0 >,
		           < 0x1e 0x0 &gpio_nw_000_031 0x1e 0x0 >,
		           < 0x1f 0x0 &gpio_nw_000_031 0x1f 0x0 >,
		           < 0x20 0x0 &gpio_nw_032_063 0x0 0x0 >,
		           < 0x21 0x0 &gpio_nw_032_063 0x1 0x0 >,
		           < 0x22 0x0 &gpio_nw_032_063 0x2 0x0 >,
		           < 0x23 0x0 &gpio_nw_032_063 0x3 0x0 >,
		           < 0x24 0x0 &gpio_nw_032_063 0x4 0x0 >,
		           < 0x25 0x0 &gpio_nw_032_063 0x5 0x0 >,
		           < 0x26 0x0 &gpio_nw_032_063 0x6 0x0 >,
		           < 0x27 0x0 &gpio_nw_032_063 0x7 0x0 >,
		           < 0x28 0x0 &gpio_nw_032_063 0x8 0x0 >,
		           < 0x29 0x0 &gpio_nw_032_063 0x9 0x0 >,
		           < 0x2a 0x0 &gpio_nw_032_063 0xa 0x0 >,
		           < 0x2b 0x0 &gpio_nw_032_063 0xb 0x0 >,
		           < 0x2c 0x0 &gpio_nw_032_063 0xc 0x0 >,
		           < 0x2d 0x0 &gpio_nw_032_063 0xd 0x0 >,
		           < 0x2e 0x0 &gpio_nw_032_063 0xe 0x0 >,
		           < 0x2f 0x0 &gpio_nw_032_063 0xf 0x0 >,
		           < 0x30 0x0 &gpio_nw_032_063 0x10 0x0 >,
		           < 0x31 0x0 &gpio_nw_032_063 0x11 0x0 >,
		           < 0x32 0x0 &gpio_nw_032_063 0x12 0x0 >,
		           < 0x33 0x0 &gpio_nw_032_063 0x13 0x0 >,
		           < 0x34 0x0 &gpio_nw_032_063 0x14 0x0 >,
		           < 0x35 0x0 &gpio_nw_032_063 0x15 0x0 >,
		           < 0x36 0x0 &gpio_nw_032_063 0x16 0x0 >,
		           < 0x37 0x0 &gpio_nw_032_063 0x17 0x0 >,
		           < 0x38 0x0 &gpio_nw_032_063 0x18 0x0 >,
		           < 0x39 0x0 &gpio_nw_032_063 0x19 0x0 >,
		           < 0x3a 0x0 &gpio_nw_032_063 0x1a 0x0 >,
		           < 0x3b 0x0 &gpio_nw_032_063 0x1b 0x0 >,
		           < 0x3c 0x0 &gpio_nw_032_063 0x1c 0x0 >,
		           < 0x3d 0x0 &gpio_nw_032_063 0x1d 0x0 >,
		           < 0x3e 0x0 &gpio_nw_032_063 0x1e 0x0 >,
		           < 0x3f 0x0 &gpio_nw_032_063 0x1f 0x0 >,
		           < 0x40 0x0 &gpio_nw_064_076 0x0 0x0 >,
		           < 0x41 0x0 &gpio_nw_064_076 0x1 0x0 >,
		           < 0x42 0x0 &gpio_nw_064_076 0x2 0x0 >,
		           < 0x43 0x0 &gpio_nw_064_076 0x3 0x0 >,
		           < 0x44 0x0 &gpio_nw_064_076 0x4 0x0 >,
		           < 0x45 0x0 &gpio_nw_064_076 0x5 0x0 >,
		           < 0x46 0x0 &gpio_nw_064_076 0x6 0x0 >,
		           < 0x47 0x0 &gpio_nw_064_076 0x7 0x0 >,
		           < 0x48 0x0 &gpio_nw_064_076 0x8 0x0 >,
		           < 0x49 0x0 &gpio_nw_064_076 0x9 0x0 >,
		           < 0x4a 0x0 &gpio_nw_064_076 0xa 0x0 >,
		           < 0x4b 0x0 &gpio_nw_064_076 0xb 0x0 >,
		           < 0x4c 0x0 &gpio_nw_064_076 0xc 0x0 >;  /* in zephyr/dts/x86/intel/apollo_lake.dtsi:500 */
	};

	/* node '/gpio-west' defined in zephyr/dts/x86/intel/apollo_lake.dtsi:579 */
	gpio_w: gpio-west {
		compatible = "intel,apollo-lake-gpio";            /* in zephyr/dts/x86/intel/apollo_lake.dtsi:581 */
		#gpio-cells = < 0x2 >;                            /* in zephyr/dts/x86/intel/apollo_lake.dtsi:582 */
		gpio-map-mask = < 0xffffffff 0xffffffc0 >;        /* in zephyr/dts/x86/intel/apollo_lake.dtsi:583 */
		gpio-map-pass-thru = < 0x0 0x3f >;                /* in zephyr/dts/x86/intel/apollo_lake.dtsi:584 */
		gpio-map = < 0x0 0x0 &gpio_w_000_031 0x0 0x0 >,
		           < 0x1 0x0 &gpio_w_000_031 0x1 0x0 >,
		           < 0x2 0x0 &gpio_w_000_031 0x2 0x0 >,
		           < 0x3 0x0 &gpio_w_000_031 0x3 0x0 >,
		           < 0x4 0x0 &gpio_w_000_031 0x4 0x0 >,
		           < 0x5 0x0 &gpio_w_000_031 0x5 0x0 >,
		           < 0x6 0x0 &gpio_w_000_031 0x6 0x0 >,
		           < 0x7 0x0 &gpio_w_000_031 0x7 0x0 >,
		           < 0x8 0x0 &gpio_w_000_031 0x8 0x0 >,
		           < 0x9 0x0 &gpio_w_000_031 0x9 0x0 >,
		           < 0xa 0x0 &gpio_w_000_031 0xa 0x0 >,
		           < 0xb 0x0 &gpio_w_000_031 0xb 0x0 >,
		           < 0xc 0x0 &gpio_w_000_031 0xc 0x0 >,
		           < 0xd 0x0 &gpio_w_000_031 0xd 0x0 >,
		           < 0xe 0x0 &gpio_w_000_031 0xe 0x0 >,
		           < 0xf 0x0 &gpio_w_000_031 0xf 0x0 >,
		           < 0x10 0x0 &gpio_w_000_031 0x10 0x0 >,
		           < 0x11 0x0 &gpio_w_000_031 0x11 0x0 >,
		           < 0x12 0x0 &gpio_w_000_031 0x12 0x0 >,
		           < 0x13 0x0 &gpio_w_000_031 0x13 0x0 >,
		           < 0x14 0x0 &gpio_w_000_031 0x14 0x0 >,
		           < 0x15 0x0 &gpio_w_000_031 0x15 0x0 >,
		           < 0x16 0x0 &gpio_w_000_031 0x16 0x0 >,
		           < 0x17 0x0 &gpio_w_000_031 0x17 0x0 >,
		           < 0x18 0x0 &gpio_w_000_031 0x18 0x0 >,
		           < 0x19 0x0 &gpio_w_000_031 0x19 0x0 >,
		           < 0x1a 0x0 &gpio_w_000_031 0x1a 0x0 >,
		           < 0x1b 0x0 &gpio_w_000_031 0x1b 0x0 >,
		           < 0x1c 0x0 &gpio_w_000_031 0x1c 0x0 >,
		           < 0x1d 0x0 &gpio_w_000_031 0x1d 0x0 >,
		           < 0x1e 0x0 &gpio_w_000_031 0x1e 0x0 >,
		           < 0x1f 0x0 &gpio_w_000_031 0x1f 0x0 >,
		           < 0x20 0x0 &gpio_w_032_046 0x0 0x0 >,
		           < 0x21 0x0 &gpio_w_032_046 0x1 0x0 >,
		           < 0x22 0x0 &gpio_w_032_046 0x2 0x0 >,
		           < 0x23 0x0 &gpio_w_032_046 0x3 0x0 >,
		           < 0x24 0x0 &gpio_w_032_046 0x4 0x0 >,
		           < 0x25 0x0 &gpio_w_032_046 0x5 0x0 >,
		           < 0x26 0x0 &gpio_w_032_046 0x6 0x0 >,
		           < 0x27 0x0 &gpio_w_032_046 0x7 0x0 >,
		           < 0x28 0x0 &gpio_w_032_046 0x8 0x0 >,
		           < 0x29 0x0 &gpio_w_032_046 0x9 0x0 >,
		           < 0x2a 0x0 &gpio_w_032_046 0xa 0x0 >,
		           < 0x2b 0x0 &gpio_w_032_046 0xb 0x0 >,
		           < 0x2c 0x0 &gpio_w_032_046 0xc 0x0 >,
		           < 0x2d 0x0 &gpio_w_032_046 0xd 0x0 >,
		           < 0x2e 0x0 &gpio_w_032_046 0xe 0x0 >;  /* in zephyr/dts/x86/intel/apollo_lake.dtsi:585 */
	};

	/* node '/gpio-southwest' defined in zephyr/dts/x86/intel/apollo_lake.dtsi:634 */
	gpio_sw: gpio-southwest {
		compatible = "intel,apollo-lake-gpio";             /* in zephyr/dts/x86/intel/apollo_lake.dtsi:636 */
		#gpio-cells = < 0x2 >;                             /* in zephyr/dts/x86/intel/apollo_lake.dtsi:637 */
		gpio-map-mask = < 0xffffffff 0xffffffc0 >;         /* in zephyr/dts/x86/intel/apollo_lake.dtsi:638 */
		gpio-map-pass-thru = < 0x0 0x3f >;                 /* in zephyr/dts/x86/intel/apollo_lake.dtsi:639 */
		gpio-map = < 0x0 0x0 &gpio_sw_000_031 0x0 0x0 >,
		           < 0x1 0x0 &gpio_sw_000_031 0x1 0x0 >,
		           < 0x2 0x0 &gpio_sw_000_031 0x2 0x0 >,
		           < 0x3 0x0 &gpio_sw_000_031 0x3 0x0 >,
		           < 0x4 0x0 &gpio_sw_000_031 0x4 0x0 >,
		           < 0x5 0x0 &gpio_sw_000_031 0x5 0x0 >,
		           < 0x6 0x0 &gpio_sw_000_031 0x6 0x0 >,
		           < 0x7 0x0 &gpio_sw_000_031 0x7 0x0 >,
		           < 0x8 0x0 &gpio_sw_000_031 0x8 0x0 >,
		           < 0x9 0x0 &gpio_sw_000_031 0x9 0x0 >,
		           < 0xa 0x0 &gpio_sw_000_031 0xa 0x0 >,
		           < 0xb 0x0 &gpio_sw_000_031 0xb 0x0 >,
		           < 0xc 0x0 &gpio_sw_000_031 0xc 0x0 >,
		           < 0xd 0x0 &gpio_sw_000_031 0xd 0x0 >,
		           < 0xe 0x0 &gpio_sw_000_031 0xe 0x0 >,
		           < 0xf 0x0 &gpio_sw_000_031 0xf 0x0 >,
		           < 0x10 0x0 &gpio_sw_000_031 0x10 0x0 >,
		           < 0x11 0x0 &gpio_sw_000_031 0x11 0x0 >,
		           < 0x12 0x0 &gpio_sw_000_031 0x12 0x0 >,
		           < 0x13 0x0 &gpio_sw_000_031 0x13 0x0 >,
		           < 0x14 0x0 &gpio_sw_000_031 0x14 0x0 >,
		           < 0x15 0x0 &gpio_sw_000_031 0x15 0x0 >,
		           < 0x16 0x0 &gpio_sw_000_031 0x16 0x0 >,
		           < 0x17 0x0 &gpio_sw_000_031 0x17 0x0 >,
		           < 0x18 0x0 &gpio_sw_000_031 0x18 0x0 >,
		           < 0x19 0x0 &gpio_sw_000_031 0x19 0x0 >,
		           < 0x1a 0x0 &gpio_sw_000_031 0x1a 0x0 >,
		           < 0x1b 0x0 &gpio_sw_000_031 0x1b 0x0 >,
		           < 0x1c 0x0 &gpio_sw_000_031 0x1c 0x0 >,
		           < 0x1d 0x0 &gpio_sw_000_031 0x1d 0x0 >,
		           < 0x1e 0x0 &gpio_sw_000_031 0x1e 0x0 >,
		           < 0x1f 0x0 &gpio_sw_000_031 0x1f 0x0 >,
		           < 0x20 0x0 &gpio_sw_032_042 0x0 0x0 >,
		           < 0x21 0x0 &gpio_sw_032_042 0x1 0x0 >,
		           < 0x22 0x0 &gpio_sw_032_042 0x2 0x0 >,
		           < 0x23 0x0 &gpio_sw_032_042 0x3 0x0 >,
		           < 0x24 0x0 &gpio_sw_032_042 0x4 0x0 >,
		           < 0x25 0x0 &gpio_sw_032_042 0x5 0x0 >,
		           < 0x26 0x0 &gpio_sw_032_042 0x6 0x0 >,
		           < 0x27 0x0 &gpio_sw_032_042 0x7 0x0 >,
		           < 0x28 0x0 &gpio_sw_032_042 0x8 0x0 >,
		           < 0x29 0x0 &gpio_sw_032_042 0x9 0x0 >,
		           < 0x2a 0x0 &gpio_sw_032_042 0xa 0x0 >;  /* in zephyr/dts/x86/intel/apollo_lake.dtsi:640 */
	};
};
